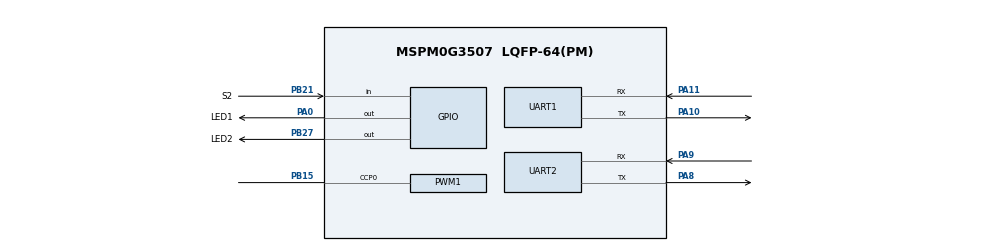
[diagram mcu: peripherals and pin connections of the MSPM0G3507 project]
//@cliArgs --device "MSPM0G350X" --package "LQFP-64(PM)" --part "Default"
//@v2CliArgs --device "MSPM0G3507" --package "LQFP-64(PM)"
// @cliArgs --board /ti/boards/LP_MSPM0G3507 --rtos nortos

/**
 * Import the modules used in this configuration.
 */
const GPIO   = scripting.addModule("/ti/driverlib/GPIO", {}, false);
const GPIO1  = GPIO.addInstance();
const GPIO2  = GPIO.addInstance();
const PWM    = scripting.addModule("/ti/driverlib/PWM", {}, false);
const PWM1   = PWM.addInstance();
const SYSCTL = scripting.addModule("/ti/driverlib/SYSCTL");
const TIMER  = scripting.addModule("/ti/driverlib/TIMER", {}, false);
const TIMER1 = TIMER.addInstance();
const TIMER2 = TIMER.addInstance();
const UART   = scripting.addModule("/ti/driverlib/UART", {}, false);
const UART1  = UART.addInstance();
const UART2  = UART.addInstance();

/**
 * Write custom configuration values to the imported modules.
 */
GPIO1.$name                          = "GPIO_GRP_0";
GPIO1.associatedPins.create(2);
GPIO1.associatedPins[0].$name        = "LED1";
GPIO1.associatedPins[0].assignedPort = "PORTA";
GPIO1.associatedPins[0].assignedPin  = "0";
GPIO1.associatedPins[0].pin.$assign  = "PA0";
GPIO1.associatedPins[1].$name        = "LED2";
GPIO1.associatedPins[1].assignedPort = "PORTB";
GPIO1.associatedPins[1].assignedPin  = "27";
GPIO1.associatedPins[1].pin.$assign  = "PB27";

const Board = scripting.addModule("/ti/driverlib/Board", {}, false);

GPIO2.$name                              = "GPIO_GRP_1";
GPIO2.associatedPins.create(2);
GPIO2.associatedPins[0].$name            = "S1";
GPIO2.associatedPins[0].direction        = "INPUT";
GPIO2.associatedPins[0].interruptEn      = true;
GPIO2.associatedPins[0].polarity         = "FALL";
GPIO2.associatedPins[0].assignedPort     = "PORTA";
GPIO2.associatedPins[0].assignedPin      = "18";
GPIO2.associatedPins[0].internalResistor = "PULL_UP";
GPIO2.associatedPins[1].$name            = "S2";
GPIO2.associatedPins[1].internalResistor = "PULL_UP";
GPIO2.associatedPins[1].direction        = "INPUT";
GPIO2.associatedPins[1].interruptEn      = true;
GPIO2.associatedPins[1].polarity         = "FALL";
GPIO2.associatedPins[1].assignedPort     = "PORTB";
GPIO2.associatedPins[1].assignedPin      = "21";
GPIO2.associatedPins[1].pin.$assign      = "PB21";

PWM1.$name                      = "PWM_0";
PWM1.ccIndex                    = [0];
PWM1.timerCount                 = 100;
PWM1.peripheral.$assign         = "TIMG7";
PWM1.peripheral.ccp0Pin.$assign = "PB15";
PWM1.PWM_CHANNEL_0.$name        = "ti_driverlib_pwm_PWMTimerCC0";

SYSCTL.forceDefaultClkConfig = true;
SYSCTL.clockTreeEn           = true;

TIMER1.$name              = "TIMER_0";
TIMER1.timerClkDiv        = 8;
TIMER1.timerClkPrescale   = 32;
TIMER1.interrupts         = ["ZERO"];
TIMER1.peripheral.$assign = "TIMG0";

TIMER2.$name              = "TIMER_1";
TIMER2.timerClkDiv        = 8;
TIMER2.timerClkPrescale   = 32;
TIMER2.interrupts         = ["ZERO"];
TIMER2.peripheral.$assign = "TIMG6";

UART1.$name                    = "UART_0";
UART1.targetBaudRate           = 115200;
UART1.peripheral.$assign       = "UART0";
UART1.peripheral.rxPin.$assign = "PA11";
UART1.peripheral.txPin.$assign = "PA10";

UART2.$name                             = "UART_1";
UART2.targetBaudRate                    = 750000;
UART2.enabledInterrupts                 = ["DMA_DONE_RX","DMA_DONE_TX","EOT_DONE"];
UART2.enabledDMARXTriggers              = "DL_UART_DMA_INTERRUPT_RX";
UART2.enabledDMATXTriggers              = "DL_UART_DMA_INTERRUPT_TX";
UART2.peripheral.$assign                = "UART1";
UART2.peripheral.rxPin.$assign          = "PA9";
UART2.peripheral.txPin.$assign          = "PA8";
UART2.DMA_CHANNEL_RX.$name              = "DMA_CH1";
UART2.DMA_CHANNEL_RX.addressMode        = "f2b";
UART2.DMA_CHANNEL_RX.srcLength          = "BYTE";
UART2.DMA_CHANNEL_RX.dstLength          = "BYTE";
UART2.DMA_CHANNEL_RX.peripheral.$assign = "DMA_CH1";
UART2.DMA_CHANNEL_TX.$name              = "DMA_CH0";
UART2.DMA_CHANNEL_TX.addressMode        = "b2f";
UART2.DMA_CHANNEL_TX.srcLength          = "BYTE";
UART2.DMA_CHANNEL_TX.dstLength          = "BYTE";
UART2.DMA_CHANNEL_TX.peripheral.$assign = "DMA_CH0";
scripting.suppress("Actual baud rate differs significantly from requested\\. Try using a                different clock source, or adjusting the baud rate or oversampling rate if needed\\.                See detailed help\\.", UART2, "calculatedError");
